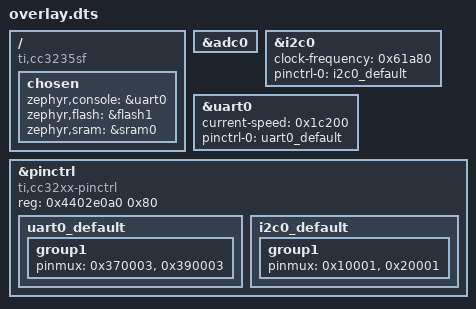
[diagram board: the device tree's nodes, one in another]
/ {
	compatible = "ti,cc3235sf", "ti,cc3235sf-launchxl", "ti,cc32xx";
	chosen {
		zephyr,console = &uart0;
		zephyr,flash = &flash1;
		zephyr,sram = &sram0;
	};
};
&adc0{
	status = "okay";
};
&i2c0{
	clock-frequency = < 0x61a80 >;
	status = "okay";
	pinctrl-0 = < &i2c0_default >;
	pinctrl-names = "default";
};
&uart0{
	status = "okay";
	current-speed = < 0x1c200 >;
	pinctrl-0 = < &uart0_default >;
	pinctrl-names = "default";
};
&pinctrl{
	compatible = "ti,cc32xx-pinctrl";
	reg = < 0x4402e0a0 0x80 >;
	uart0_default: uart0_default {
		group1 {
			pinmux = < 0x370003 >, < 0x390003 >;
		};
	};
	i2c0_default: i2c0_default {
		group1 {
			pinmux = < 0x10001 >, < 0x20001 >;
		};
	};
};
